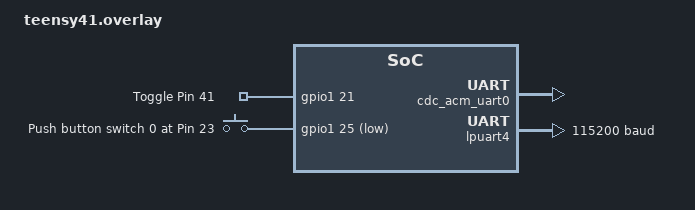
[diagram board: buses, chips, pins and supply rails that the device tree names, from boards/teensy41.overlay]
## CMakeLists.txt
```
# SPDX-License-Identifier: Apache-2.0

cmake_minimum_required(VERSION 3.20.0)
find_package(Zephyr REQUIRED HINTS $ENV{ZEPHYR_BASE})
project(dhcpv4_client)

FILE(GLOB app_sources src/*.c)
target_sources(app PRIVATE ${app_sources})

# zephyr_code_relocate(src/*.c DTCM_DATA)
# zephyr_code_relocate(src/*.c ITCM_TEXT)
```

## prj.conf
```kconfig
# GENERAL
# CONFIG_CODE_DATA_RELOCATION=y
CONFIG_LOG=y
CONFIG_GPIO=y

# SDHC
CONFIG_FILE_SYSTEM=y
CONFIG_FAT_FILESYSTEM_ELM=y
# CONFIG_SDMMC_USDHC=y

# USB (incl. console output)
CONFIG_USB_DEVICE_STACK=y
# CONFIG_USB_UART_CONSOLE=y
CONFIG_USB_DRIVER_LOG_LEVEL_ERR=y
CONFIG_USB_DEVICE_PRODUCT="TEENSY USB CONSOLE"
CONFIG_USB_DEVICE_VID=0x2FE4
CONFIG_UART_INTERRUPT_DRIVEN=y
CONFIG_UART_LINE_CTRL=y

CONFIG_SERIAL=y
CONFIG_CONSOLE=y
CONFIG_UART_CONSOLE=y
CONFIG_UART_LINE_CTRL=y

# ETH
CONFIG_NETWORKING=y
CONFIG_NET_IPV6=n
CONFIG_NET_IPV4=y
CONFIG_NET_DHCPV4=y

CONFIG_NET_MGMT=y
CONFIG_NET_MGMT_EVENT=y

CONFIG_NET_L2_ETHERNET=y
CONFIG_MDIO=y
CONFIG_MDIO_NXP_MCUX=y


CONFIG_NET_IF_UNICAST_IPV4_ADDR_COUNT=2
CONFIG_NET_IF_MCAST_IPV4_ADDR_COUNT=2
CONFIG_NET_IF_MAX_IPV4_COUNT=10
CONFIG_NET_IPV4_AUTO=y
# # CONFIG_NET_IPV4_LOG_LEVEL_DBG=y
# # CONFIG_NET_IPV4_AUTO_LOG_LEVEL_DBG=y
# CONFIG_NET_ICMPV4_LOG_LEVEL_DBG=y
# CONFIG_NET_DHCPV4_LOG_LEVEL_DBG=y
CONFIG_NET_DHCPV4_INITIAL_DELAY_MAX=10
CONFIG_NET_STATISTICS=y

CONFIG_NET_ARP=y
CONFIG_NET_SHELL=y
CONFIG_NET_CONFIG_AUTO_INIT=y

CONFIG_NET_LOG=y


# CONFIG_NET_CONFIG_SETTINGS=n
# CONFIG_NET_CONFIG_NEED_IPV6=n
# CONFIG_NET_CONFIG_NEED_IPV4=y
# CONFIG_NET_CONFIG_MY_IPV4_ADDR="192.168.179.233"
# CONFIG_NET_CONFIG_MY_IPV4_NETMASK="255.255.255.0"



# SPI
CONFIG_SPI=y


# Floating Point Options
CONFIG_FPU=y
CONFIG_FPU_SHARING=y

# enable POSIX date and time api
CONFIG_POSIX_CLOCK=y

# enable the function sys_reboot()
CONFIG_REBOOT=y


# For using the shell
CONFIG_SHELL_PROMPT_UART="teensy:~$ "
CONFIG_PRINTK=y
CONFIG_SHELL=y
# Priority for backend is default 0 CDC ACM device initializes at POST_KERNEL at CONFIG_SHELL_BACKEND_SERIAL_INIT_PRIORITY which defaults to 50.
CONFIG_SHELL_BACKEND_SERIAL_INIT_PRIORITY=51
CONFIG_SHELL_BACKEND_SERIAL=y
# # CONFIG_OBJECT_TRACING=y
CONFIG_THREAD_MONITOR=y
# CONFIG_INIT_STACKS=y
# CONFIG_BOOT_BANNER=n
CONFIG_THREAD_NAME=y
CONFIG_SHELL_HISTORY=y
CONFIG_SHELL_STACK_SIZE=2048
CONFIG_SHELL_CMD_BUFF_SIZE=128
# CONFIG_SHELL_WILDCARD=y
# # CONFIG_SHELL_DYNAMIC_CMDS=n
CONFIG_SHELL_VT100_COLORS=y
# CONFIG_SHELL_HELP_ON_WRONG_ARGUMENT_COUNT=y
CONFIG_SHELL_STATS=y
CONFIG_SHELL_CMDS=y
CONFIG_SHELL_HELP=y
CONFIG_SHELL_TAB=y
# CONFIG_SHELL_METAKEYS=y
CONFIG_SHELL_LOG_BACKEND=y
CONFIG_KERNEL_SHELL=y
CONFIG_DEVICE_SHELL=y
# CONFIG_DATE_SHELL=y
# CONFIG_CBPRINTF_NANO=y
CONFIG_SENSOR_SHELL=n
CONFIG_SHELL_CMDS_SELECT=y
```

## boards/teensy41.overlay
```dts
/*
 * Copyright (c) 2020, Bernhard Kraemer
 *
 * SPDX-License-Identifier: Apache-2.0
 */

/ {
    aliases {
      toggle = &toggle_gpio;
      sw0 = &button0;
    };

    chosen {
      zephyr,console = &cdc_acm_uart0;
      zephyr,shell-uart = &cdc_acm_uart0;
    };

    app-gpios {
      compatible = "gpio-keys";
      toggle_gpio: toggle-gpio {
        gpios = <&gpio1 21 GPIO_ACTIVE_HIGH>;
        label = "Toggle Pin 41";
      };
      button0: button_0 {
        gpios = < &gpio1 25 GPIO_ACTIVE_LOW >;
        label = "Push button switch 0 at Pin 23";
      };
    };
};

// &enet2{
//   status = "okay";
// };

&zephyr_udc0 {
  cdc_acm_uart0: cdc_acm_uart0 {
    compatible = "zephyr,cdc-acm-uart";
    label = "CDC_ACM_0";
  };
};

&lpuart6 {
  status = "disabled";
};

&lpuart4 {
  status = "okay";
  current-speed = < 115200 >;
};
```

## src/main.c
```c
/* Networking DHCPv4 client */

/*
 * Copyright (c) 2017 ARM Ltd.
 * Copyright (c) 2016 Intel Corporation.
 *
 * SPDX-License-Identifier: Apache-2.0
 */

#include <zephyr/logging/log.h>
LOG_MODULE_REGISTER(net_dhcpv4_client_sample, LOG_LEVEL_DBG);

#include <zephyr/device.h>
// #include <linker/sections.h>
#include <errno.h>
#include <stdio.h>

#include <zephyr/net/net_if.h>
#include <zephyr/net/net_core.h>
#include <zephyr/net/net_context.h>
#include <zephyr/net/net_mgmt.h>

#include <zephyr/usb/usb_device.h>

static struct net_mgmt_event_callback mgmt_cb;

static void handler(struct net_mgmt_event_callback *cb,
		    uint32_t mgmt_event,
		    struct net_if *iface)
{
	int i = 0;

	if (mgmt_event != NET_EVENT_IPV4_ADDR_ADD) {
		return;
	}

	for (i = 0; i < NET_IF_MAX_IPV4_ADDR; i++) {
		char buf[NET_IPV4_ADDR_LEN];

		if (iface->config.ip.ipv4->unicast[i].addr_type !=
							NET_ADDR_DHCP) {
			continue;
		}

		LOG_INF("Your address: %s",
			net_addr_ntop(AF_INET,
			    &iface->config.ip.ipv4->unicast[i].address.in_addr,
						  buf, sizeof(buf)));
		LOG_INF("Lease time: %u seconds",
			 iface->config.dhcpv4.lease_time);
		LOG_INF("Subnet: %s",
			net_addr_ntop(AF_INET,
				       &iface->config.ip.ipv4->netmask,
				       buf, sizeof(buf)));
		LOG_INF("Router: %s",
			net_addr_ntop(AF_INET,
						 &iface->config.ip.ipv4->gw,
						 buf, sizeof(buf)));
	}
}

void main(void)
{
	if (usb_enable(NULL)) {
		return;
	}

	struct net_if *iface;

	net_mgmt_init_event_callback(&mgmt_cb, handler,
				     NET_EVENT_IPV4_ADDR_ADD);
	net_mgmt_add_event_callback(&mgmt_cb);

	iface = net_if_get_default();

	net_dhcpv4_start(iface);
}
```
